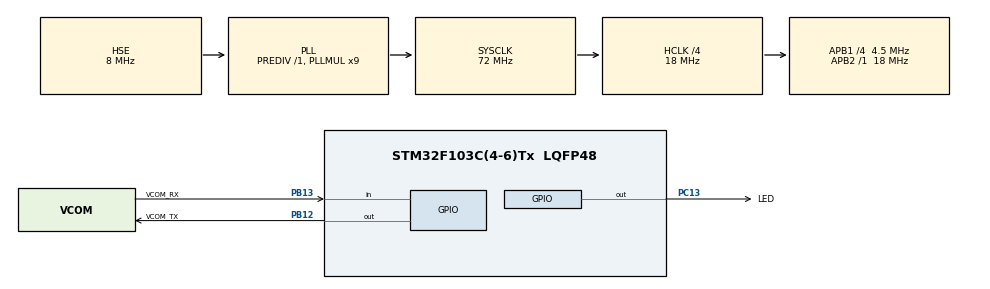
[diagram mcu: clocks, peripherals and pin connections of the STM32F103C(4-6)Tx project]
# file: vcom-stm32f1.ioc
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Mcu.Family=STM32F1
Mcu.Name=STM32F103C(4-6)Tx
Mcu.Package=LQFP48
NVIC.PriorityGroup=NVIC_PRIORITYGROUP_4
NVIC.TIM3_IRQn=true\:0\:0\:false\:false\:true\:true\:true\:true
PB12.GPIO_Label=VCOM_TX
PB12.GPIO_ModeDefaultOutputPP=GPIO_MODE_OUTPUT_PP
PB12.GPIO_PuPd=GPIO_PULLUP
PB12.GPIO_Speed=GPIO_SPEED_FREQ_HIGH
PB12.PinState=GPIO_PIN_SET
PB12.Signal=GPIO_Output
PB13.GPIO_Label=VCOM_RX
PB13.GPIO_PuPd=GPIO_PULLUP
PB13.Signal=GPIO_Input
PC13-TAMPER-RTC.GPIO_Label=LED
PC13-TAMPER-RTC.PinState=GPIO_PIN_RESET
PC13-TAMPER-RTC.Signal=GPIO_Output
PC14-OSC32_IN.Mode=LSE-External-Oscillator
PC14-OSC32_IN.Signal=RCC_OSC32_IN
PC15-OSC32_OUT.Mode=LSE-External-Oscillator
PC15-OSC32_OUT.Signal=RCC_OSC32_OUT
PD0-OSC_IN.Mode=HSE-External-Oscillator
PD0-OSC_IN.Signal=RCC_OSC_IN
PD1-OSC_OUT.Mode=HSE-External-Oscillator
PD1-OSC_OUT.Signal=RCC_OSC_OUT
ProjectManager.HeapSize=0x200
ProjectManager.StackSize=0x400
ProjectManager.TargetToolchain=STM32CubeIDE
RCC.AHBCLKDivider=RCC_SYSCLK_DIV4
RCC.AHBFreq_Value=18000000
RCC.APB1CLKDivider=RCC_HCLK_DIV4
RCC.APB1Freq_Value=4500000
RCC.APB1TimFreq_Value=9000000
RCC.APB2Freq_Value=18000000
RCC.APB2TimFreq_Value=18000000
RCC.HCLKFreq_Value=18000000
RCC.PLLMUL=RCC_PLL_MUL9
RCC.PLLSourceVirtual=RCC_PLLSOURCE_HSE
RCC.RTCClockSelection=RCC_RTCCLKSOURCE_LSE
RCC.SYSCLKFreq_VALUE=72000000
RCC.SYSCLKSource=RCC_SYSCLKSOURCE_PLLCLK
RCC.USBFreq_Value=72000000
TIM3.AutoReloadPreload=TIM_AUTORELOAD_PRELOAD_ENABLE
TIM3.CounterMode=TIM_COUNTERMODE_DOWN
TIM3.Period=1
TIM3.Prescaler=833
VP_SYS_VS_ND.Mode=No_Debug
VP_TIM3_VS_ClockSourceINT.Mode=Internal
board=custom

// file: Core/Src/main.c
/* USER CODE BEGIN Header */
/**
  ******************************************************************************
  * @file           : main.c
  * @brief          : Main program body
  ******************************************************************************
  * @attention
  *
  * Copyright (c) 2023 STMicroelectronics.
  * All rights reserved.
  *
  * This software is licensed under terms that can be found in the LICENSE file
  * in the root directory of this software component.
  * If no LICENSE file comes with this software, it is provided AS-IS.
  *
  ******************************************************************************
  */
/* USER CODE END Header */
#include "main.h"

/* USER CODE BEGIN Includes */
#include <stdint.h>
#include <inttypes.h>
#include "vcom.h"
#include "vcom_interface.h"
#include <stm32f1xx_hal.h>
#include <stm32f1xx_hal_gpio.h>
/* USER CODE END Includes */

TIM_HandleTypeDef htim3;

/* USER CODE BEGIN PV */
vcom_handle_t hvcom1;
/* USER CODE END PV */

void SystemClock_Config(void);
static void MX_GPIO_Init(void);
static void MX_TIM3_Init(void);

int main(void)
{
  /* USER CODE BEGIN 1 */
  char msg[200];
  uint32_t msg_len;
  /* USER CODE END 1 */

  /* MCU Configuration--------------------------------------------------------*/

  /* Reset of all peripherals, Initializes the Flash interface and the Systick. */
  HAL_Init();

  /* Configure the system clock */
  SystemClock_Config();

  /* Initialize all configured peripherals */
  MX_GPIO_Init();
  MX_TIM3_Init();
  /* USER CODE BEGIN 2 */
  HAL_Delay(2000);

  hvcom1.delay_timer_init = vcom_interface_timer_init;
  hvcom1.delay_timer_deinit = vcom_interface_timer_deint;
  hvcom1.delay_timer_start = vcom_interface_timer_start;
  hvcom1.delay_timer_stop = vcom_interface_timer_stop;
//   hvcom1.delay_timer_wait = vcom_interface_timer_wait;
  hvcom1.tx_gpio_init = vcom_interface_tx_gpio_init;
  hvcom1.tx_gpio_deinit = vcom_interface_timer_deint;
  hvcom1.tx_gpio_write = vcom_interface_tx_gpio_wirte;
  if (vcom_init(&hvcom1, 9600) != 0) {
    Error_Handler();
  }
  /* USER CODE END 2 */

  /* Infinite loop */
  /* USER CODE BEGIN WHILE */
  while (1)
  {
      if (hvcom1.tx_done == 1) {
        msg_len = snprintf(msg, 200, "%"PRIu32" hello\n", HAL_GetTick());
        vcom_transmit(&hvcom1, msg, msg_len);
        HAL_Delay(1000);
      }
    /* USER CODE END WHILE */

  }
}

void SystemClock_Config(void)
{
  RCC_OscInitTypeDef RCC_OscInitStruct = {0};
  RCC_ClkInitTypeDef RCC_ClkInitStruct = {0};

  /** Initializes the RCC Oscillators according to the specified parameters
  * in the RCC_OscInitTypeDef structure.
  */
  RCC_OscInitStruct.OscillatorType = RCC_OSCILLATORTYPE_HSE;
  RCC_OscInitStruct.HSEState = RCC_HSE_ON;
  RCC_OscInitStruct.HSEPredivValue = RCC_HSE_PREDIV_DIV1;
  RCC_OscInitStruct.HSIState = RCC_HSI_ON;
  RCC_OscInitStruct.PLL.PLLState = RCC_PLL_ON;
  RCC_OscInitStruct.PLL.PLLSource = RCC_PLLSOURCE_HSE;
  RCC_OscInitStruct.PLL.PLLMUL = RCC_PLL_MUL9;
  if (HAL_RCC_OscConfig(&RCC_OscInitStruct) != HAL_OK)
  {
    Error_Handler();
  }

  /** Initializes the CPU, AHB and APB buses clocks
  */
  RCC_ClkInitStruct.ClockType = RCC_CLOCKTYPE_HCLK|RCC_CLOCKTYPE_SYSCLK
                              |RCC_CLOCKTYPE_PCLK1|RCC_CLOCKTYPE_PCLK2;
  RCC_ClkInitStruct.SYSCLKSource = RCC_SYSCLKSOURCE_PLLCLK;
  RCC_ClkInitStruct.AHBCLKDivider = RCC_SYSCLK_DIV4;
  RCC_ClkInitStruct.APB1CLKDivider = RCC_HCLK_DIV4;
  RCC_ClkInitStruct.APB2CLKDivider = RCC_HCLK_DIV1;

  if (HAL_RCC_ClockConfig(&RCC_ClkInitStruct, FLASH_LATENCY_2) != HAL_OK)
  {
    Error_Handler();
  }
}

static void MX_TIM3_Init(void)
{

  TIM_ClockConfigTypeDef sClockSourceConfig = {0};
  TIM_MasterConfigTypeDef sMasterConfig = {0};

  htim3.Instance = TIM3;
  htim3.Init.Prescaler = 833;
  htim3.Init.CounterMode = TIM_COUNTERMODE_DOWN;
  htim3.Init.Period = 1;
  htim3.Init.ClockDivision = TIM_CLOCKDIVISION_DIV1;
  htim3.Init.AutoReloadPreload = TIM_AUTORELOAD_PRELOAD_ENABLE;
  if (HAL_TIM_Base_Init(&htim3) != HAL_OK)
  {
    Error_Handler();
  }
  sClockSourceConfig.ClockSource = TIM_CLOCKSOURCE_INTERNAL;
  if (HAL_TIM_ConfigClockSource(&htim3, &sClockSourceConfig) != HAL_OK)
  {
    Error_Handler();
  }
  sMasterConfig.MasterOutputTrigger = TIM_TRGO_RESET;
  sMasterConfig.MasterSlaveMode = TIM_MASTERSLAVEMODE_DISABLE;
  if (HAL_TIMEx_MasterConfigSynchronization(&htim3, &sMasterConfig) != HAL_OK)
  {
    Error_Handler();
  }

}

static void MX_GPIO_Init(void)
{
  GPIO_InitTypeDef GPIO_InitStruct = {0};

  /* GPIO Ports Clock Enable */
  __HAL_RCC_GPIOC_CLK_ENABLE();
  __HAL_RCC_GPIOD_CLK_ENABLE();
  __HAL_RCC_GPIOB_CLK_ENABLE();

  /*Configure GPIO pin Output Level */
  HAL_GPIO_WritePin(LED_GPIO_Port, LED_Pin, GPIO_PIN_RESET);

  /*Configure GPIO pin Output Level */
  HAL_GPIO_WritePin(VCOM_TX_GPIO_Port, VCOM_TX_Pin, GPIO_PIN_SET);

  /*Configure GPIO pin : LED_Pin */
  GPIO_InitStruct.Pin = LED_Pin;
  GPIO_InitStruct.Mode = GPIO_MODE_OUTPUT_PP;
  GPIO_InitStruct.Pull = GPIO_NOPULL;
  GPIO_InitStruct.Speed = GPIO_SPEED_FREQ_LOW;
  HAL_GPIO_Init(LED_GPIO_Port, &GPIO_InitStruct);

  /*Configure GPIO pin : VCOM_TX_Pin */
  GPIO_InitStruct.Pin = VCOM_TX_Pin;
  GPIO_InitStruct.Mode = GPIO_MODE_OUTPUT_PP;
  GPIO_InitStruct.Pull = GPIO_PULLUP;
  GPIO_InitStruct.Speed = GPIO_SPEED_FREQ_HIGH;
  HAL_GPIO_Init(VCOM_TX_GPIO_Port, &GPIO_InitStruct);

  /*Configure GPIO pin : VCOM_RX_Pin */
  GPIO_InitStruct.Pin = VCOM_RX_Pin;
  GPIO_InitStruct.Mode = GPIO_MODE_INPUT;
  GPIO_InitStruct.Pull = GPIO_PULLUP;
  HAL_GPIO_Init(VCOM_RX_GPIO_Port, &GPIO_InitStruct);

}

/* USER CODE BEGIN 4 */
void HAL_TIM_PeriodElapsedCallback(TIM_HandleTypeDef *htim)
{
    if (htim == &htim3) {
        vcom_transfer(&hvcom1);
    }
}
/* USER CODE END 4 */

void Error_Handler(void)
{
  __disable_irq();
  while (1)
  {
  }
}
